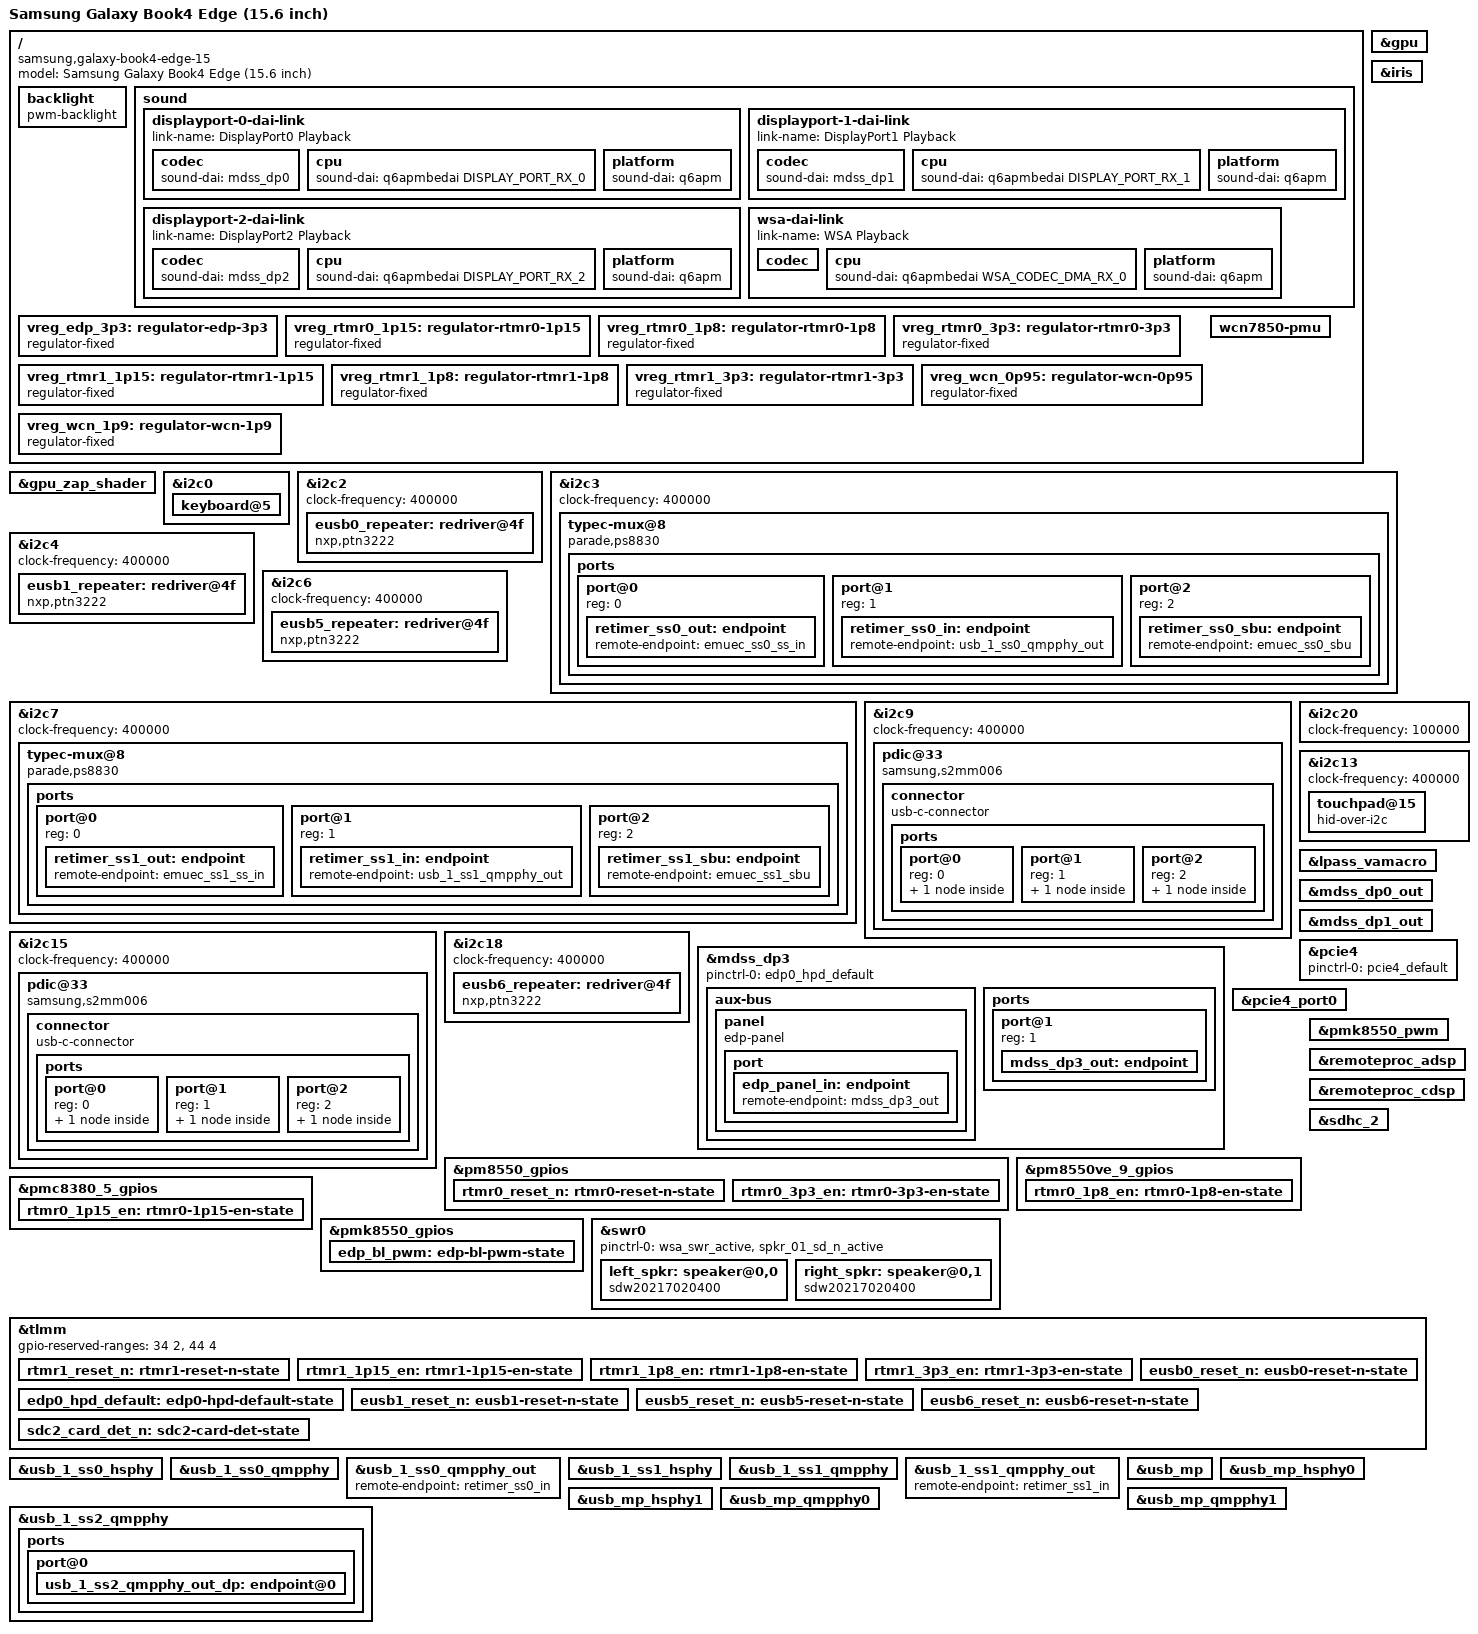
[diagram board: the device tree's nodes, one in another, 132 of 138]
// SPDX-License-Identifier: BSD-3-Clause
/*
 * Copyright (c) 2023 Qualcomm Innovation Center, Inc. All rights reserved.
 * Copyright (c) 2025 Kirill A. Korinsky <kirill@korins.ky>
 * Copyright (c) 2025 Valentin Manea <valentin.manea@mrs.ro>
 * Copyright (c) 2026 Antheas Kapenekakis <lkml@antheas.dev>
 */

/dts-v1/;

#include "purwa.dtsi"
#include "hamoa-pmics.dtsi"
#include "x1-samsung-galaxy-book4-edge.dtsi"

/delete-node/ &pmc8380_6;
/delete-node/ &pmc8380_6_thermal;

/ {
	model = "Samsung Galaxy Book4 Edge (15.6 inch)";
	compatible = "samsung,galaxy-book4-edge-15",
		     "samsung,galaxy-book4-edge",
		     "qcom,x1p42100";

	backlight: backlight {
		compatible = "pwm-backlight";
		pwms = <&pmk8550_pwm 0 416667>;
		enable-gpios = <&pmc8380_3_gpios 4 GPIO_ACTIVE_HIGH>;

		pinctrl-0 = <&edp_bl_en>, <&edp_bl_pwm>;
		pinctrl-names = "default";
	};

	sound {
		model = "X1P42100-GalaxyBook4Edge";
		audio-routing = "SpkrLeft IN", "WSA WSA_SPK1 OUT",
				"SpkrRight IN", "WSA WSA_SPK2 OUT",
				"IN1_HPHL", "HPHL_OUT",
				"IN2_HPHR", "HPHR_OUT",
				"AMIC2", "MIC BIAS2",
				"VA DMIC0", "MIC BIAS3",
				"VA DMIC1", "MIC BIAS3",
				"VA DMIC2", "MIC BIAS1",
				"VA DMIC3", "MIC BIAS1",
				"TX SWR_INPUT1", "ADC2_OUTPUT";

		displayport-0-dai-link {
			link-name = "DisplayPort0 Playback";

			codec {
				sound-dai = <&mdss_dp0>;
			};

			cpu {
				sound-dai = <&q6apmbedai DISPLAY_PORT_RX_0>;
			};

			platform {
				sound-dai = <&q6apm>;
			};
		};

		displayport-1-dai-link {
			link-name = "DisplayPort1 Playback";

			codec {
				sound-dai = <&mdss_dp1>;
			};

			cpu {
				sound-dai = <&q6apmbedai DISPLAY_PORT_RX_1>;
			};

			platform {
				sound-dai = <&q6apm>;
			};
		};

		displayport-2-dai-link {
			link-name = "DisplayPort2 Playback";

			codec {
				sound-dai = <&mdss_dp2>;
			};

			cpu {
				sound-dai = <&q6apmbedai DISPLAY_PORT_RX_2>;
			};

			platform {
				sound-dai = <&q6apm>;
			};
		};

		wsa-dai-link {
			link-name = "WSA Playback";

			codec {
				sound-dai = <&left_spkr>, <&right_spkr>,
					    <&swr0 0>, <&lpass_wsamacro 0>;
			};

			cpu {
				sound-dai = <&q6apmbedai WSA_CODEC_DMA_RX_0>;
			};

			platform {
				sound-dai = <&q6apm>;
			};
		};
	};

	vreg_edp_3p3: regulator-edp-3p3 {
		compatible = "regulator-fixed";

		regulator-name = "VREG_EDP_3P3";
		regulator-min-microvolt = <3300000>;
		regulator-max-microvolt = <3300000>;

		gpio = <&tlmm 70 GPIO_ACTIVE_LOW>;

		pinctrl-0 = <&edp_reg_en>;
		pinctrl-names = "default";

		startup-delay-us = <1000>;
		regulator-enable-ramp-delay = <1000>;

		vin-supply = <&vreg_display_vdd>;

		regulator-always-on;
		regulator-boot-on;
	};

	vreg_rtmr0_1p15: regulator-rtmr0-1p15 {
		compatible = "regulator-fixed";
		regulator-name = "VREG_RTMR0_1P15";
		regulator-min-microvolt = <1150000>;
		regulator-max-microvolt = <1150000>;
		gpio = <&pmc8380_5_gpios 8 GPIO_ACTIVE_HIGH>;
		enable-active-high;
		pinctrl-0 = <&rtmr0_1p15_en>;
		pinctrl-names = "default";
		regulator-boot-on;
	};

	vreg_rtmr0_1p8: regulator-rtmr0-1p8 {
		compatible = "regulator-fixed";
		regulator-name = "VREG_RTMR0_1P8";
		regulator-min-microvolt = <1800000>;
		regulator-max-microvolt = <1800000>;
		gpio = <&pm8550ve_9_gpios 8 GPIO_ACTIVE_HIGH>;
		enable-active-high;
		pinctrl-0 = <&rtmr0_1p8_en>;
		pinctrl-names = "default";
		regulator-boot-on;
	};

	vreg_rtmr0_3p3: regulator-rtmr0-3p3 {
		compatible = "regulator-fixed";
		regulator-name = "VREG_RTMR0_3P3";
		regulator-min-microvolt = <3300000>;
		regulator-max-microvolt = <3300000>;
		gpio = <&pm8550_gpios 11 GPIO_ACTIVE_HIGH>;
		enable-active-high;
		pinctrl-0 = <&rtmr0_3p3_en>;
		pinctrl-names = "default";
		regulator-boot-on;
	};

	vreg_rtmr1_1p15: regulator-rtmr1-1p15 {
		compatible = "regulator-fixed";
		regulator-name = "VREG_RTMR1_1P15";
		regulator-min-microvolt = <1150000>;
		regulator-max-microvolt = <1150000>;
		gpio = <&tlmm 188 GPIO_ACTIVE_HIGH>;
		enable-active-high;
		pinctrl-0 = <&rtmr1_1p15_en>;
		pinctrl-names = "default";
		regulator-boot-on;
	};

	vreg_rtmr1_1p8: regulator-rtmr1-1p8 {
		compatible = "regulator-fixed";
		regulator-name = "VREG_RTMR1_1P8";
		regulator-min-microvolt = <1800000>;
		regulator-max-microvolt = <1800000>;
		gpio = <&tlmm 175 GPIO_ACTIVE_HIGH>;
		enable-active-high;
		pinctrl-0 = <&rtmr1_1p8_en>;
		pinctrl-names = "default";
		regulator-boot-on;
	};

	vreg_rtmr1_3p3: regulator-rtmr1-3p3 {
		compatible = "regulator-fixed";
		regulator-name = "VREG_RTMR1_3P3";
		regulator-min-microvolt = <3300000>;
		regulator-max-microvolt = <3300000>;
		gpio = <&tlmm 186 GPIO_ACTIVE_HIGH>;
		enable-active-high;
		pinctrl-0 = <&rtmr1_3p3_en>;
		pinctrl-names = "default";
		regulator-boot-on;
	};

	vreg_wcn_0p95: regulator-wcn-0p95 {
		compatible = "regulator-fixed";

		regulator-name = "VREG_WCN_0P95";
		regulator-min-microvolt = <950000>;
		regulator-max-microvolt = <950000>;

		vin-supply = <&vreg_wcn_3p3>;
	};

	vreg_wcn_1p9: regulator-wcn-1p9 {
		compatible = "regulator-fixed";

		regulator-name = "VREG_WCN_1P9";
		regulator-min-microvolt = <1900000>;
		regulator-max-microvolt = <1900000>;

		vin-supply = <&vreg_wcn_3p3>;
	};

	wcn7850-pmu {
		vdd-supply = <&vreg_wcn_0p95>;
		vddio-supply = <&vreg_l15b_1p8>;
		vddaon-supply = <&vreg_wcn_0p95>;
		vdddig-supply = <&vreg_wcn_0p95>;
		vddrfa1p2-supply = <&vreg_wcn_1p9>;
		vddrfa1p8-supply = <&vreg_wcn_1p9>;
	};
};

&gpu {
	status = "okay";
};

&gpu_zap_shader {
	firmware-name = "qcom/x1p42100/SAMSUNG/NP750XQB/qcdxkmsucpurwa.mbn";
};

&iris {
	firmware-name = "qcom/x1p42100/SAMSUNG/NP750XQB/qcvss8380.mbn";

	status = "okay";
};

&i2c0 {
	keyboard@5 {
		vdd-supply = <&vreg_misc_3p3>;
		vddl-supply = <&vreg_l15b_1p8>;
	};
};

&i2c2 {
	clock-frequency = <400000>;

	status = "okay";

	eusb0_repeater: redriver@4f {
		compatible = "nxp,ptn3222";
		reg = <0x4f>;
		#phy-cells = <0>;

		vdd3v3-supply = <&vreg_l2b_3p0>;
		vdd1v8-supply = <&vreg_l3d_1p8>;

		reset-gpios = <&tlmm 10 GPIO_ACTIVE_LOW>;

		pinctrl-0 = <&eusb0_reset_n>;
		pinctrl-names = "default";
	};
};

&i2c3 {
	clock-frequency = <400000>;
	status = "okay";

	typec-mux@8 {
		compatible = "parade,ps8830";
		reg = <0x08>;

		clocks = <&rpmhcc RPMH_RF_CLK3>;

		vdd-supply = <&vreg_rtmr0_1p15>;
		vdd33-supply = <&vreg_rtmr0_3p3>;
		vdd33-cap-supply = <&vreg_rtmr0_3p3>;
		vddar-supply = <&vreg_rtmr0_1p15>;
		vddat-supply = <&vreg_rtmr0_1p15>;
		vddio-supply = <&vreg_rtmr0_1p8>;

		reset-gpios = <&pm8550_gpios 10 GPIO_ACTIVE_LOW>;
		pinctrl-0 = <&rtmr0_reset_n>;
		pinctrl-names = "default";

		orientation-switch;
		retimer-switch;

		ports {
			#address-cells = <1>;
			#size-cells = <0>;

			port@0 {
				reg = <0>;
				retimer_ss0_out: endpoint {
					remote-endpoint = <&emuec_ss0_ss_in>;
				};
			};

			port@1 {
				reg = <1>;
				retimer_ss0_in: endpoint {
					remote-endpoint = <&usb_1_ss0_qmpphy_out>;
				};
			};

			port@2 {
				reg = <2>;
				retimer_ss0_sbu: endpoint {
					remote-endpoint = <&emuec_ss0_sbu>;
				};
			};
		};
	};
};

&i2c4 {
	clock-frequency = <400000>;

	status = "okay";

	eusb1_repeater: redriver@4f {
		compatible = "nxp,ptn3222";
		reg = <0x4f>;
		#phy-cells = <0>;

		vdd3v3-supply = <&vreg_l14b_3p0>;
		vdd1v8-supply = <&vreg_l3d_1p8>;

		reset-gpios = <&tlmm 19 GPIO_ACTIVE_LOW>;

		pinctrl-0 = <&eusb1_reset_n>;
		pinctrl-names = "default";
	};
};

&i2c6 {
	clock-frequency = <400000>;

	status = "okay";

	eusb5_repeater: redriver@4f {
		compatible = "nxp,ptn3222";
		reg = <0x4f>;
		#phy-cells = <0>;

		vdd3v3-supply = <&vreg_l8b_3p0>;
		vdd1v8-supply = <&vreg_l3d_1p8>;

		reset-gpios = <&tlmm 26 GPIO_ACTIVE_LOW>;

		pinctrl-0 = <&eusb5_reset_n>;
		pinctrl-names = "default";
	};
};

&i2c7 {
	clock-frequency = <400000>;
	status = "okay";

	typec-mux@8 {
		compatible = "parade,ps8830";
		reg = <0x08>;

		clocks = <&rpmhcc RPMH_RF_CLK4>;

		vdd-supply = <&vreg_rtmr1_1p15>;
		vdd33-supply = <&vreg_rtmr1_3p3>;
		vdd33-cap-supply = <&vreg_rtmr1_3p3>;
		vddar-supply = <&vreg_rtmr1_1p15>;
		vddat-supply = <&vreg_rtmr1_1p15>;
		vddio-supply = <&vreg_rtmr1_1p8>;

		reset-gpios = <&tlmm 176 GPIO_ACTIVE_LOW>;
		pinctrl-0 = <&rtmr1_reset_n>;
		pinctrl-names = "default";

		orientation-switch;
		retimer-switch;

		ports {
			#address-cells = <1>;
			#size-cells = <0>;

			port@0 {
				reg = <0>;
				retimer_ss1_out: endpoint {
					remote-endpoint = <&emuec_ss1_ss_in>;
				};
			};

			port@1 {
				reg = <1>;
				retimer_ss1_in: endpoint {
					remote-endpoint = <&usb_1_ss1_qmpphy_out>;
				};
			};

			port@2 {
				reg = <2>;
				retimer_ss1_sbu: endpoint {
					remote-endpoint = <&emuec_ss1_sbu>;
				};
			};
		};
	};
};

/* The two S2MM006 USB-C controllers are at 0x33 on these buses. */
&i2c9 {
	clock-frequency = <400000>;
	status = "okay";

	pdic@33 {
		compatible = "samsung,s2mm006";
		reg = <0x33>;
		interrupts-extended = <&tlmm 38 IRQ_TYPE_LEVEL_LOW>;

		/* Left-side rear port */
		connector {
			compatible = "usb-c-connector";
			power-role = "dual";
			data-role = "dual";

			ports {
				#address-cells = <1>;
				#size-cells = <0>;

				port@0 {
					reg = <0>;

					emuec_ss0_hs_in: endpoint {
						remote-endpoint = <&usb_1_ss0_dwc3_hs>;
					};
				};

				port@1 {
					reg = <1>;

					emuec_ss0_ss_in: endpoint {
						remote-endpoint = <&retimer_ss0_out>;
					};
				};

				port@2 {
					reg = <2>;

					emuec_ss0_sbu: endpoint {
						remote-endpoint = <&retimer_ss0_sbu>;
					};
				};
			};
		};
	};
};

&i2c15 {
	clock-frequency = <400000>;
	status = "okay";

	pdic@33 {
		compatible = "samsung,s2mm006";
		reg = <0x33>;
		interrupts-extended = <&tlmm 93 IRQ_TYPE_LEVEL_LOW>;

		/* Left-side front port */
		connector {
			compatible = "usb-c-connector";
			power-role = "dual";
			data-role = "dual";

			ports {
				#address-cells = <1>;
				#size-cells = <0>;

				port@0 {
					reg = <0>;

					emuec_ss1_hs_in: endpoint {
						remote-endpoint = <&usb_1_ss1_dwc3_hs>;
					};
				};

				port@1 {
					reg = <1>;

					emuec_ss1_ss_in: endpoint {
						remote-endpoint = <&retimer_ss1_out>;
					};
				};

				port@2 {
					reg = <2>;

					emuec_ss1_sbu: endpoint {
						remote-endpoint = <&retimer_ss1_sbu>;
					};
				};
			};
		};
	};
};

&i2c18 {
	clock-frequency = <400000>;

	status = "okay";

	eusb6_repeater: redriver@4f {
		compatible = "nxp,ptn3222";
		reg = <0x4f>;
		#phy-cells = <0>;

		vdd3v3-supply = <&vreg_l13b_3p0>;
		vdd1v8-supply = <&vreg_l4b_1p8>;

		reset-gpios = <&tlmm 74 GPIO_ACTIVE_LOW>;

		pinctrl-0 = <&eusb6_reset_n>;
		pinctrl-names = "default";
	};
};

/* The ISL9238-family charger and SBS battery use 0x09 and 0x0b on this bus. */
&i2c20 {
	clock-frequency = <100000>;
	status = "okay";
};

&i2c13 {
	clock-frequency = <400000>;

	status = "okay";

	touchpad@15 {
		compatible = "hid-over-i2c";
		reg = <0x15>;

		hid-descr-addr = <0x1>;
		interrupts-extended = <&tlmm 3 IRQ_TYPE_LEVEL_LOW>;

		vdd-supply = <&vreg_misc_3p3>;
		vddl-supply = <&vreg_l15b_1p8>;

		pinctrl-0 = <&tpad_default>;
		pinctrl-names = "default";

		wakeup-source;
	};
};

&lpass_vamacro {
	pinctrl-0 = <&dmic01_default>, <&dmic23_default>;
	pinctrl-names = "default";

	vdd-micb-supply = <&vreg_l1b_1p8>;
	qcom,dmic-sample-rate = <2400000>;
};

&mdss_dp0_out {
	data-lanes = <0 1 2 3>;
	link-frequencies = /bits/ 64 <1620000000 2700000000 5400000000>;
};

&mdss_dp1_out {
	data-lanes = <0 1 2 3>;
	link-frequencies = /bits/ 64 <1620000000 2700000000 5400000000>;
};

&mdss_dp3 {
	/delete-property/ #sound-dai-cells;

	pinctrl-0 = <&edp0_hpd_default>;
	pinctrl-names = "default";

	status = "okay";

	aux-bus {
		panel: panel {
			compatible = "edp-panel";

			backlight = <&backlight>;
			power-supply = <&vreg_edp_3p3>;
			no-hpd;

			port {
				edp_panel_in: endpoint {
					remote-endpoint = <&mdss_dp3_out>;
				};
			};
		};
	};

	ports {
		port@1 {
			reg = <1>;
			mdss_dp3_out: endpoint {
				data-lanes = <0 1 2 3>;
				link-frequencies = /bits/ 64 <1620000000 2700000000 5400000000>;

				remote-endpoint = <&edp_panel_in>;
			};
		};
	};
};

&pcie4 {
	pinctrl-0 = <&pcie4_default>;
	pinctrl-names = "default";

	status = "okay";
};

&pcie4_port0 {
	reset-gpios = <&tlmm 146 GPIO_ACTIVE_LOW>;
	wake-gpios = <&tlmm 148 GPIO_ACTIVE_LOW>;
};

&pm8550_gpios {
	rtmr0_reset_n: rtmr0-reset-n-state {
		pins = "gpio10";
		function = "normal";
		power-source = <1>;
		bias-disable;
		input-disable;
		output-enable;
	};

	rtmr0_3p3_en: rtmr0-3p3-en-state {
		pins = "gpio11";
		function = "normal";
		power-source = <1>;
		bias-disable;
		input-disable;
		output-enable;
	};
};

&pm8550ve_9_gpios {
	rtmr0_1p8_en: rtmr0-1p8-en-state {
		pins = "gpio8";
		function = "normal";
		power-source = <1>;
		bias-disable;
		input-disable;
		output-enable;
	};
};

&pmc8380_5_gpios {
	rtmr0_1p15_en: rtmr0-1p15-en-state {
		pins = "gpio8";
		function = "normal";
		power-source = <1>;
		bias-disable;
		input-disable;
		output-enable;
	};
};

&pmk8550_gpios {
	edp_bl_pwm: edp-bl-pwm-state {
		pins = "gpio5";
		function = "func3";
	};
};

&pmk8550_pwm {
	status = "okay";
};

&remoteproc_adsp {
	firmware-name = "qcom/x1p42100/SAMSUNG/NP750XQB/qcadsp8380.mbn",
			"qcom/x1p42100/SAMSUNG/NP750XQB/adsp_dtbs.elf";

	status = "okay";
};

&remoteproc_cdsp {
	firmware-name = "qcom/x1p42100/SAMSUNG/NP750XQB/qccdsp8380.mbn",
			"qcom/x1p42100/SAMSUNG/NP750XQB/cdsp_dtbs.elf";

	status = "okay";
};

&sdhc_2 {
	cd-gpios = <&tlmm 71 GPIO_ACTIVE_LOW>;
	pinctrl-0 = <&sdc2_default &sdc2_card_det_n>;
	pinctrl-1 = <&sdc2_sleep &sdc2_card_det_n>;
	pinctrl-names = "default", "sleep";
	vmmc-supply = <&vreg_l9b_2p9>;
	vqmmc-supply = <&vreg_l6b_1p8>;
	bus-width = <4>;
	no-sdio;
	no-mmc;

	status = "okay";
};

&swr0 {
	status = "okay";

	pinctrl-0 = <&wsa_swr_active>, <&spkr_01_sd_n_active>;
	pinctrl-names = "default";

	/* WSA8845, Left Speaker */
	left_spkr: speaker@0,0 {
		compatible = "sdw20217020400";
		reg = <0 0>;
		reset-gpios = <&lpass_tlmm 12 GPIO_ACTIVE_LOW>;
		#sound-dai-cells = <0>;
		sound-name-prefix = "SpkrLeft";
		vdd-1p8-supply = <&vreg_l15b_1p8>;
		vdd-io-supply = <&vreg_l12b_1p2>;
		qcom,port-mapping = <1 2 3 7 10 13>;
	};

	/* WSA8845, Right Speaker */
	right_spkr: speaker@0,1 {
		compatible = "sdw20217020400";
		reg = <0 1>;
		reset-gpios = <&lpass_tlmm 12 GPIO_ACTIVE_LOW>;
		#sound-dai-cells = <0>;
		sound-name-prefix = "SpkrRight";
		vdd-1p8-supply = <&vreg_l15b_1p8>;
		vdd-io-supply = <&vreg_l12b_1p2>;
		qcom,port-mapping = <4 5 6 7 11 13>;
	};
};

&tlmm {
	gpio-reserved-ranges = <34 2>, /* Unused */
			       <44 4>;

 /* SPI (TPM) */

	rtmr1_reset_n: rtmr1-reset-n-state {
		pins = "gpio176";
		function = "gpio";
		drive-strength = <2>;
		bias-disable;
	};

	rtmr1_1p15_en: rtmr1-1p15-en-state {
		pins = "gpio188";
		function = "gpio";
		drive-strength = <2>;
		bias-disable;
	};

	rtmr1_1p8_en: rtmr1-1p8-en-state {
		pins = "gpio175";
		function = "gpio";
		drive-strength = <2>;
		bias-disable;
	};

	rtmr1_3p3_en: rtmr1-3p3-en-state {
		pins = "gpio186";
		function = "gpio";
		drive-strength = <2>;
		bias-disable;
	};

	edp0_hpd_default: edp0-hpd-default-state {
		/delete-property/ bias-disable;

		pins = "gpio119";
		function = "edp0_hot";
		bias-pull-down;
		drive-strength = <2>;
	};

	eusb0_reset_n: eusb0-reset-n-state {
		pins = "gpio10";
		function = "gpio";
		drive-strength = <2>;
		bias-disable;
		output-low;
	};

	eusb1_reset_n: eusb1-reset-n-state {
		pins = "gpio19";
		function = "gpio";
		drive-strength = <2>;
		bias-disable;
		output-low;
	};

	eusb5_reset_n: eusb5-reset-n-state {
		pins = "gpio26";
		function = "gpio";
		drive-strength = <2>;
		bias-disable;
		output-low;
	};

	eusb6_reset_n: eusb6-reset-n-state {
		pins = "gpio74";
		function = "gpio";
		drive-strength = <2>;
		bias-disable;
		output-low;
	};

	sdc2_card_det_n: sdc2-card-det-state {
		pins = "gpio71";
		function = "gpio";
		drive-strength = <2>;
		bias-pull-up;
	};
};

&usb_1_ss0_hsphy {
	vdd-supply = <&vreg_l3j_0p8>;
	vdda12-supply = <&vreg_l2j_1p2>;
	phys = <&eusb0_repeater>;

	status = "okay";
};

&usb_1_ss0_qmpphy {
	vdda-phy-supply = <&vreg_l1j_0p8>;
	vdda-pll-supply = <&vreg_l2j_1p2>;

	status = "okay";
};

&usb_1_ss0_qmpphy_out {
	remote-endpoint = <&retimer_ss0_in>;
};

&usb_1_ss1_hsphy {
	vdd-supply = <&vreg_l3j_0p8>;
	vdda12-supply = <&vreg_l2j_1p2>;
	phys = <&eusb1_repeater>;

	status = "okay";
};

&usb_1_ss1_qmpphy {
	vdda-phy-supply = <&vreg_l2d_0p9>;
	vdda-pll-supply = <&vreg_l2j_1p2>;

	status = "okay";
};

&usb_1_ss1_qmpphy_out {
	remote-endpoint = <&retimer_ss1_in>;
};

&usb_1_ss2_qmpphy {
	vdda-phy-supply = <&vreg_l2d_0p9>;
	vdda-pll-supply = <&vreg_l2j_1p2>;

	/delete-property/ mode-switch;
	/delete-property/ orientation-switch;

	status = "okay";

	ports {
		port@0 {
			#address-cells = <1>;
			#size-cells = <0>;

			/delete-node/ endpoint;

			usb_1_ss2_qmpphy_out_dp: endpoint@0 {
				reg = <0>;

				data-lanes = <3 2 1 0>;
				remote-endpoint = <&hdmi_bridge_dp_in>;
			};
		};
	};
};

/* MP0 goes to the USB-A port (USB3) and FPC */
&usb_mp {
	status = "okay";
};

&usb_mp_hsphy0 {
	vdd-supply = <&vreg_l2e_0p8>;
	vdda12-supply = <&vreg_l3e_1p2>;

	phys = <&eusb5_repeater>;

	status = "okay";
};

&usb_mp_hsphy1 {
	vdd-supply = <&vreg_l2e_0p8>;
	vdda12-supply = <&vreg_l3e_1p2>;

	phys = <&eusb6_repeater>;

	status = "okay";
};

&usb_mp_qmpphy0 {
	vdda-phy-supply = <&vreg_l3c_0p8>;
	vdda-pll-supply = <&vreg_l3e_1p2>;

	status = "okay";
};

&usb_mp_qmpphy1 {
	vdda-phy-supply = <&vreg_l3c_0p8>;
	vdda-pll-supply = <&vreg_l3e_1p2>;

	status = "okay";
};
